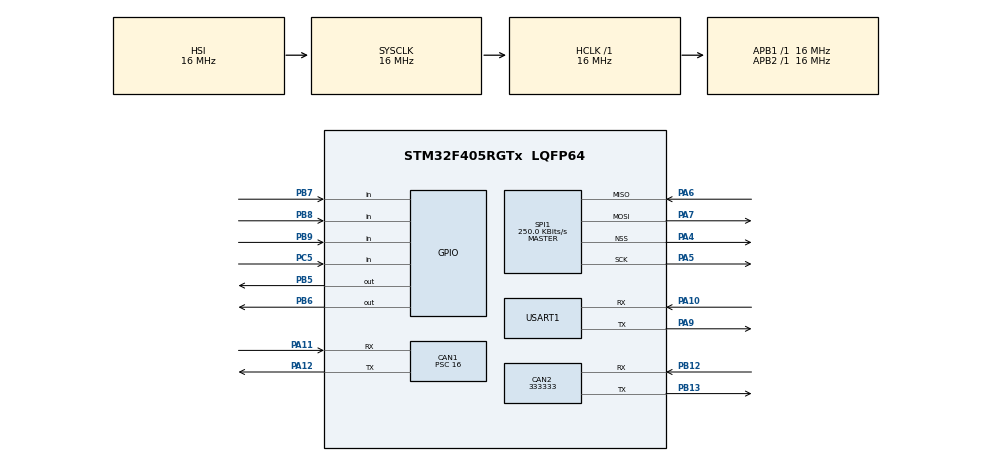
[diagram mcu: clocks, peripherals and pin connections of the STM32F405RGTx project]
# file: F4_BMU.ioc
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CAN1.ABOM=DISABLE
CAN1.AWUM=DISABLE
CAN1.BS1=CAN_BS1_1TQ
CAN1.BS2=CAN_BS2_1TQ
CAN1.CalculateBaudRate=333333
CAN1.CalculateTimeBit=3000
CAN1.CalculateTimeQuantum=1000.0
CAN1.Mode=CAN_MODE_LOOPBACK
CAN1.NART=DISABLE
CAN1.Prescaler=16
CAN1.RFLM=DISABLE
CAN1.TTCM=DISABLE
CAN1.TXFP=DISABLE
CAN2.BS1=CAN_BS1_1TQ
CAN2.BS2=CAN_BS2_1TQ
CAN2.CalculateBaudRate=333333
CAN2.CalculateTimeBit=3000
CAN2.CalculateTimeQuantum=1000.0
CAN2.Mode=CAN_MODE_SILENT_LOOPBACK
Mcu.Family=STM32F4
Mcu.Name=STM32F405RGTx
Mcu.Package=LQFP64
NVIC.PriorityGroup=NVIC_PRIORITYGROUP_4
NVIC.USART1_IRQn=true\:0\:0\:false\:false\:true\:true\:true\:true
PA10.Mode=Asynchronous
PA10.Signal=USART1_RX
PA11.GPIO_PuPd=GPIO_PULLUP
PA11.Mode=CAN_Activate
PA11.Signal=CAN1_RX
PA12.GPIO_PuPd=GPIO_PULLUP
PA12.Mode=CAN_Activate
PA12.Signal=CAN1_TX
PA13.Mode=JTAG_4_pins
PA13.Signal=SYS_JTMS-SWDIO
PA14.Mode=JTAG_4_pins
PA14.Signal=SYS_JTCK-SWCLK
PA15.Mode=JTAG_4_pins
PA15.Signal=SYS_JTDI
PA4.Mode=NSS_Signal_Hard_Output
PA4.Signal=SPI1_NSS
PA5.Mode=Full_Duplex_Master
PA5.Signal=SPI1_SCK
PA6.Mode=Full_Duplex_Master
PA6.Signal=SPI1_MISO
PA7.Mode=Full_Duplex_Master
PA7.Signal=SPI1_MOSI
PA9.Mode=Asynchronous
PA9.Signal=USART1_TX
PB12.GPIO_PuPd=GPIO_PULLUP
PB12.Mode=CAN_Activate
PB12.Signal=CAN2_RX
PB13.GPIO_PuPd=GPIO_PULLUP
PB13.Mode=CAN_Activate
PB13.Signal=CAN2_TX
PB3.Mode=JTAG_4_pins
PB3.Signal=SYS_JTDO-SWO
PB5.Signal=GPIO_Output
PB6.Signal=GPIO_Output
PB7.Signal=GPIO_Input
PB8.Signal=GPIO_Input
PB9.Signal=GPIO_Input
PC5.Signal=GPIO_Input
ProjectManager.HeapSize=0x200
ProjectManager.StackSize=0x400
ProjectManager.TargetToolchain=STM32CubeIDE
RCC.AHBFreq_Value=16000000
RCC.APB1Freq_Value=16000000
RCC.APB1TimFreq_Value=16000000
RCC.APB2Freq_Value=16000000
RCC.APB2TimFreq_Value=16000000
RCC.CortexFreq_Value=16000000
RCC.HCLKFreq_Value=16000000
RCC.HSE_VALUE=25000000
RCC.HSI_VALUE=16000000
RCC.LSE_VALUE=32768
RCC.SYSCLKFreq_VALUE=16000000
RCC.VCOOutputFreq_Value=192000000
SPI1.BaudRatePrescaler=SPI_BAUDRATEPRESCALER_64
SPI1.CalculateBaudRate=250.0 KBits/s
SPI1.DataSize=SPI_DATASIZE_8BIT
SPI1.Direction=SPI_DIRECTION_2LINES
SPI1.Mode=SPI_MODE_MASTER
SPI1.VirtualNSS=VM_NSSHARD
SPI1.VirtualType=VM_MASTER
USART1.VirtualMode=VM_ASYNC
board=custom

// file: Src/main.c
/* USER CODE BEGIN Header */
/**
  ******************************************************************************
  * @file           : main.c
  * @brief          : Main program body
  ******************************************************************************
  * @attention
  *
  * Copyright (c) 2024 STMicroelectronics.
  * All rights reserved.
  *
  * This software is licensed under terms that can be found in the LICENSE file
  * in the root directory of this software component.
  * If no LICENSE file comes with this software, it is provided AS-IS.
  *
  ******************************************************************************
  */
/* USER CODE END Header */
#include "main.h"

/* USER CODE BEGIN Includes */
#include <stdio.h>
/* USER CODE END Includes */

/* USER CODE BEGIN PTD */
#define CHARGING 0x4545

/* USER CODE END PTD */

CAN_HandleTypeDef hcan1;
CAN_HandleTypeDef hcan2;

SPI_HandleTypeDef hspi1;

UART_HandleTypeDef huart1;

void SystemClock_Config(void);
static void MX_GPIO_Init(void);
static void MX_CAN1_Init(void);
static void MX_CAN2_Init(void);
static void MX_SPI1_Init(void);
static void MX_USART1_UART_Init(void);

int main(void)
{

  /* MCU Configuration--------------------------------------------------------*/

  /* Reset of all peripherals, Initializes the Flash interface and the Systick. */
  HAL_Init();

  /* Configure the system clock */
  SystemClock_Config();

  /* Initialize all configured peripherals */
  MX_GPIO_Init();
  MX_CAN1_Init();
  MX_CAN2_Init();
  MX_SPI1_Init();
  MX_USART1_UART_Init();
  /* USER CODE BEGIN 2 */
  static uint8_t txbuff[] = "UART OUT\n";
  static uint8_t spibuff[] = "SPI OUt\n";
  //static uint8_t data[1];

  /* USER CODE END 2 */

  /* Infinite loop */
  while (1)
  {

    /* USER CODE BEGIN 3 */
	  HAL_UART_Transmit(&huart1, txbuff, sizeof(txbuff), 100);
	  HAL_Delay(1000);

	  HAL_SPI_Transmit(&hspi1, spibuff, sizeof(spibuff), 100);
	  HAL_Delay(1000);

  }
  /* USER CODE END 3 */
}

void SystemClock_Config(void)
{
  RCC_OscInitTypeDef RCC_OscInitStruct = {0};
  RCC_ClkInitTypeDef RCC_ClkInitStruct = {0};

  /** Configure the main internal regulator output voltage
  */
  __HAL_RCC_PWR_CLK_ENABLE();
  __HAL_PWR_VOLTAGESCALING_CONFIG(PWR_REGULATOR_VOLTAGE_SCALE1);

  /** Initializes the RCC Oscillators according to the specified parameters
  * in the RCC_OscInitTypeDef structure.
  */
  RCC_OscInitStruct.OscillatorType = RCC_OSCILLATORTYPE_HSI;
  RCC_OscInitStruct.HSIState = RCC_HSI_ON;
  RCC_OscInitStruct.HSICalibrationValue = RCC_HSICALIBRATION_DEFAULT;
  RCC_OscInitStruct.PLL.PLLState = RCC_PLL_NONE;
  if (HAL_RCC_OscConfig(&RCC_OscInitStruct) != HAL_OK)
  {
    Error_Handler();
  }

  /** Initializes the CPU, AHB and APB buses clocks
  */
  RCC_ClkInitStruct.ClockType = RCC_CLOCKTYPE_HCLK|RCC_CLOCKTYPE_SYSCLK
                              |RCC_CLOCKTYPE_PCLK1|RCC_CLOCKTYPE_PCLK2;
  RCC_ClkInitStruct.SYSCLKSource = RCC_SYSCLKSOURCE_HSI;
  RCC_ClkInitStruct.AHBCLKDivider = RCC_SYSCLK_DIV1;
  RCC_ClkInitStruct.APB1CLKDivider = RCC_HCLK_DIV1;
  RCC_ClkInitStruct.APB2CLKDivider = RCC_HCLK_DIV1;

  if (HAL_RCC_ClockConfig(&RCC_ClkInitStruct, FLASH_LATENCY_0) != HAL_OK)
  {
    Error_Handler();
  }
}

static void MX_CAN1_Init(void)
{

  hcan1.Instance = CAN1;
  hcan1.Init.Prescaler = 16;
  hcan1.Init.Mode = CAN_MODE_LOOPBACK;
  hcan1.Init.SyncJumpWidth = CAN_SJW_1TQ;
  hcan1.Init.TimeSeg1 = CAN_BS1_1TQ;
  hcan1.Init.TimeSeg2 = CAN_BS2_1TQ;
  hcan1.Init.TimeTriggeredMode = DISABLE;
  hcan1.Init.AutoBusOff = DISABLE;
  hcan1.Init.AutoWakeUp = DISABLE;
  hcan1.Init.AutoRetransmission = DISABLE;
  hcan1.Init.ReceiveFifoLocked = DISABLE;
  hcan1.Init.TransmitFifoPriority = DISABLE;
  if (HAL_CAN_Init(&hcan1) != HAL_OK)
  {
    Error_Handler();
  }

}

static void MX_CAN2_Init(void)
{

  hcan2.Instance = CAN2;
  hcan2.Init.Prescaler = 16;
  hcan2.Init.Mode = CAN_MODE_SILENT_LOOPBACK;
  hcan2.Init.SyncJumpWidth = CAN_SJW_1TQ;
  hcan2.Init.TimeSeg1 = CAN_BS1_1TQ;
  hcan2.Init.TimeSeg2 = CAN_BS2_1TQ;
  hcan2.Init.TimeTriggeredMode = DISABLE;
  hcan2.Init.AutoBusOff = DISABLE;
  hcan2.Init.AutoWakeUp = DISABLE;
  hcan2.Init.AutoRetransmission = DISABLE;
  hcan2.Init.ReceiveFifoLocked = DISABLE;
  hcan2.Init.TransmitFifoPriority = DISABLE;
  if (HAL_CAN_Init(&hcan2) != HAL_OK)
  {
    Error_Handler();
  }

}

static void MX_SPI1_Init(void)
{

  /* SPI1 parameter configuration*/
  hspi1.Instance = SPI1;
  hspi1.Init.Mode = SPI_MODE_MASTER;
  hspi1.Init.Direction = SPI_DIRECTION_2LINES;
  hspi1.Init.DataSize = SPI_DATASIZE_8BIT;
  hspi1.Init.CLKPolarity = SPI_POLARITY_LOW;
  hspi1.Init.CLKPhase = SPI_PHASE_1EDGE;
  hspi1.Init.NSS = SPI_NSS_HARD_OUTPUT;
  hspi1.Init.BaudRatePrescaler = SPI_BAUDRATEPRESCALER_64;
  hspi1.Init.FirstBit = SPI_FIRSTBIT_MSB;
  hspi1.Init.TIMode = SPI_TIMODE_DISABLE;
  hspi1.Init.CRCCalculation = SPI_CRCCALCULATION_DISABLE;
  hspi1.Init.CRCPolynomial = 10;
  if (HAL_SPI_Init(&hspi1) != HAL_OK)
  {
    Error_Handler();
  }

}

static void MX_USART1_UART_Init(void)
{

  huart1.Instance = USART1;
  huart1.Init.BaudRate = 115200;
  huart1.Init.WordLength = UART_WORDLENGTH_8B;
  huart1.Init.StopBits = UART_STOPBITS_1;
  huart1.Init.Parity = UART_PARITY_NONE;
  huart1.Init.Mode = UART_MODE_TX_RX;
  huart1.Init.HwFlowCtl = UART_HWCONTROL_NONE;
  huart1.Init.OverSampling = UART_OVERSAMPLING_16;
  if (HAL_UART_Init(&huart1) != HAL_OK)
  {
    Error_Handler();
  }

}

static void MX_GPIO_Init(void)
{
  GPIO_InitTypeDef GPIO_InitStruct = {0};

  /* GPIO Ports Clock Enable */
  __HAL_RCC_GPIOA_CLK_ENABLE();
  __HAL_RCC_GPIOC_CLK_ENABLE();
  __HAL_RCC_GPIOB_CLK_ENABLE();

  /*Configure GPIO pin Output Level */
  HAL_GPIO_WritePin(GPIOB, GPIO_PIN_5|GPIO_PIN_6, GPIO_PIN_RESET);

  /*Configure GPIO pin : PC5 */
  GPIO_InitStruct.Pin = GPIO_PIN_5;
  GPIO_InitStruct.Mode = GPIO_MODE_INPUT;
  GPIO_InitStruct.Pull = GPIO_NOPULL;
  HAL_GPIO_Init(GPIOC, &GPIO_InitStruct);

  /*Configure GPIO pins : PB5 PB6 */
  GPIO_InitStruct.Pin = GPIO_PIN_5|GPIO_PIN_6;
  GPIO_InitStruct.Mode = GPIO_MODE_OUTPUT_PP;
  GPIO_InitStruct.Pull = GPIO_NOPULL;
  GPIO_InitStruct.Speed = GPIO_SPEED_FREQ_LOW;
  HAL_GPIO_Init(GPIOB, &GPIO_InitStruct);

  /*Configure GPIO pins : PB7 PB8 PB9 */
  GPIO_InitStruct.Pin = GPIO_PIN_7|GPIO_PIN_8|GPIO_PIN_9;
  GPIO_InitStruct.Mode = GPIO_MODE_INPUT;
  GPIO_InitStruct.Pull = GPIO_NOPULL;
  HAL_GPIO_Init(GPIOB, &GPIO_InitStruct);

}

void Error_Handler(void)
{
  __disable_irq();
  while (1)
  {
  }
}
